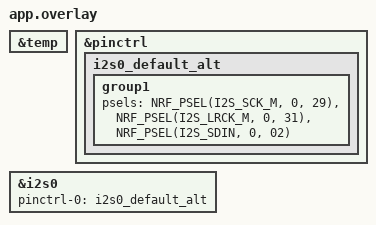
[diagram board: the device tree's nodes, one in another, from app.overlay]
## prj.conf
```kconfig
# BLE
CONFIG_BT=y #enable bluetooth 
CONFIG_LOG=y #Logging
CONFIG_BT_LOG_LEVEL_WRN=y
CONFIG_BT_PERIPHERAL=y #enable periphery service
CONFIG_BT_DEVICE_NAME="Temp and Light" # name used in advertising
CONFIG_BT_DEVICE_APPEARANCE=833 

# SENSORS 
CONFIG_SENSOR=y
CONFIG_TEMP_NRF5=y

# Secure FOTA 
# CONFIG_BOOTLOADER_MCUBOOT=y

# Audio configs 
CONFIG_I2S=y

# DSP Configs
CONFIG_REQUIRES_FULL_LIBC=y
CONFIG_REQUIRES_FLOAT_PRINTF=y
CONFIG_CMSIS_DSP=y
CONFIG_CMSIS_DSP_STATISTICS=y
CONFIG_CMSIS_DSP_FILTERING=y
CONFIG_CBPRINTF_FP_SUPPORT=y
CONFIG_CMSIS_DSP_TRANSFORM=y

# State Machine Configs
CONFIG_SMF=y
```

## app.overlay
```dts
&temp {
	status = "okay"; 
};


&pinctrl {
	/*Assign pins to i2s so we can use mic*/
	i2s0_default_alt: i2s0_default_alt {
		group1 {
			psels = <NRF_PSEL(I2S_SCK_M, 0, 29)>,
				<NRF_PSEL(I2S_LRCK_M, 0, 31)>,
				<NRF_PSEL(I2S_SDIN, 0, 02)>;
		};
	};
};


/*Activate the i2s peripheral by setting status to ok*/
&i2s0{
	status = "okay";
	pinctrl-0 = <&i2s0_default_alt>;
	pinctrl-names = "default";
};
```

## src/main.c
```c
/*
 * Copyright (c) gaiaochos.com
 * SPDX-License-Identifier: Apache-2.0
 */
#include <zephyr/device.h>
#include <zephyr/kernel.h>
#include <zephyr/logging/log.h>

#include "app.h"
#include "audio_service.h"
#include "ble_service.h"
#include "temperature.h"
#include "fsm_service.h"
#include "inference_service.h"

// Enable logs
LOG_MODULE_REGISTER(custom_service_log);

#define THREAD_STACK_SIZE 1024

K_MSGQ_DEFINE(tempmsgq, TEMP_MSG_SIZE, TEMPQSIZE, 2);
K_THREAD_DEFINE(temp_thread_id, THREAD_STACK_SIZE, temp_sensor_thread, NULL, NULL, NULL, 5, 0, 0); 
K_THREAD_DEFINE(ble_temp_thread_id, THREAD_STACK_SIZE, ble_temp_read_thread, NULL, NULL, NULL, 6, 0,0);
K_THREAD_DEFINE(audio_thread_id, THREAD_STACK_SIZE, audio_sense_thread, NULL, NULL, NULL, 4, 0, 0);
K_THREAD_DEFINE(fsm_thread_id, THREAD_STACK_SIZE, fsm_run_thread, NULL, NULL, NULL, 3, 0 , 0);
K_THREAD_DEFINE(inference_thread_id, THREAD_STACK_SIZE, inference_thread_run, NULL, NULL, NULL, 6, 0, 0);
int main(void) { 
   /*State Machine*/
   fsm_init();

  /*Blocking bluetooth init*/
  ble_service_init();

  /*Bluetooth setup was a success do sensor now*/
  sensor_temp_sensor_init();

  /*Inference Thread Init*/
  inference_init();

  /*Audio Service init*/
  audio_service_init();
 
  /*This becomes our idle loop*/
  while (1) {
    k_sleep(K_SECONDS(2));
  }
}
```

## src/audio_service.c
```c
#include <zephyr/logging/log.h>

#include "audio_service.h"
#include "fsm_service.h"

LOG_MODULE_REGISTER(audio_module);

K_MEM_SLAB_DEFINE_STATIC(mem_slab, BLOCK_SIZE, BLOCK_COUNT, 4);
K_MEM_SLAB_DEFINE(inference_slab, BLOCK_SIZE, BLOCK_COUNT, 4);
K_FIFO_DEFINE(infer_fifo);


static const struct device *i2s_dev;

void audio_service_init()
{
	i2s_dev = DEVICE_DT_GET(DT_NODELABEL(i2s0));
	struct i2s_config config;
	int ret;

	config.word_size = SAMPLE_BIT_WIDTH;
	config.channels = NUMBER_OF_CHANNELS;
	config.format = I2S_FMT_DATA_FORMAT_I2S;
	config.options = I2S_OPT_BIT_CLK_MASTER | I2S_OPT_FRAME_CLK_MASTER;
	config.frame_clk_freq = SAMPLE_FREQUENCY;
	config.mem_slab = &mem_slab;
	config.block_size = BLOCK_SIZE;
	config.timeout = TIMEOUT_MS;

	ret = i2s_configure(i2s_dev, I2S_DIR_RX, &config);
	if (ret < 0) {
		LOG_ERR("Failed to configure I2S RX: %d\n", ret);
		return;
	}

	if (!device_is_ready(i2s_dev)) {
		LOG_ERR("I2S device not ready\n");
		return;
	}
}

void audio_sense_thread(void *arg1, void *arg2, void *arg3)
{
	int ret;

	while (1) {
		/*Wait on a semaphore*/
		k_sem_take(&mic_sense_gate, K_FOREVER);

		/* Post an Event to FSM to show MIC capturing*/
		fsm_post_event(EVENT_AUD_SENSE_STARTED);



		/*Check the audio sense gate before working*/
		void *mem_block;
		void *infer_block;
		uint32_t size;

		ret = i2s_trigger(i2s_dev, I2S_DIR_RX, I2S_TRIGGER_START);
		if (ret < 0) {
			LOG_ERR("Failed to start I2S RX: %d \n", ret);
			return;
		}

		LOG_WRN("SENSING AUDIO");
		ret = i2s_read(i2s_dev, &mem_block, &size);
		if (ret == 0) {
			for (int b = 1; b <= 3; b++) {
				ret = k_mem_slab_alloc(&inference_slab, (void **)&infer_block,
						       K_NO_WAIT);
				if (ret == 0) {
					memset(infer_block, 0, size); 
					memcpy(infer_block, mem_block, size);
					k_fifo_put(&infer_fifo, infer_block);
					k_mem_slab_free(&mem_slab, (void *)mem_block);
				} else {
					LOG_ERR("Could not allocate Infer block (%d)", ret);
				}
			}

		} else {
			LOG_ERR("I2S Failed to read %d", ret);
		}

		// 3. Stop capture, then drop any packes
		i2s_trigger(i2s_dev, I2S_DIR_RX, I2S_TRIGGER_STOP);
		i2s_trigger(i2s_dev, I2S_DIR_RX, I2S_TRIGGER_DROP);

		// 4. Sleep before next cycle
		k_sem_give(&mic_sense_gate);
		//SEND A STATE EVENT TO TRIGGER FILTERING
		fsm_post_event(EVENT_AUD_SENSE_END);
		k_sleep(K_SECONDS(2));
	}
}
```

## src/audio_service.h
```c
#ifndef AUDIO_SERVICE_H
#define AUDIO_SERVIC_H
#include <zephyr/device.h>
#include <zephyr/drivers/i2s.h>

#define SAMPLE_FREQUENCY 	44100
/*Mic data sheet*/
#define SAMPLE_BIT_WIDTH 	24
/*24 Bits packed into a 32 bit block*/
#define BYTES_PER_SAMPLE 	sizeof(int32_t)
#define NUMBER_OF_CHANNELS 	1
/*4410 samples so 0.1s
 * Swapped to 4096 because our FFT implementation demands that.
 * */
#define SAMPLES_PER_BLOCK 	4096 //((SAMPLE_FREQUENCY / 10) * NUMBER_OF_CHANNELS)
#define INITIAL_BLOCK_COUNT 	1
#define TIMEOUT_MS 		2000

/*Because i2s_read expects number of bytes*/
#define BLOCK_SIZE 		(BYTES_PER_SAMPLE * SAMPLES_PER_BLOCK) 
/*Enough for 400ms of sound*/
#define BLOCK_COUNT		(INITIAL_BLOCK_COUNT + 3)


/*Filter  Definitions*/
#define NUM_TAPS			53

extern struct k_mem_slab inference_slab;
extern struct k_fifo infer_fifo; 

void audio_service_init();
void audio_sense_thread(void *arg1, void *arg2, void *arg3);
#endif
```

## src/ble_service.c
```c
#include "zephyr/bluetooth/conn.h"
#include <zephyr/bluetooth/bluetooth.h>
#include <zephyr/bluetooth/gatt.h>
#include <zephyr/bluetooth/uuid.h>
#include <zephyr/logging/log.h>
LOG_MODULE_REGISTER(ble_module);

#include "app.h"
#include "ble_service.h"
#include "fsm_service.h"


extern struct state_object state_object;
extern struct k_msgq tempmsgq;

volatile bool ble_ready = false;
float temp_float;

/* Error checking function to make sure ble runs well.
 * Enables us to report on Bluetooth
 */
void bt_ready(int err) {
  if (err) {
    LOG_ERR("bt enable return %d", err);
  }
  LOG_INF("bt ready!");
  ble_ready = true;
}

/* Defining the advertising packets
 * An advertising packet has
 * 1. The name of the service
 * 2. Connection paramters such as intervals
 */
static const struct bt_data advert[] = {
    // enable ble and stop classic bluetooth
    BT_DATA_BYTES(BT_DATA_FLAGS, (BT_LE_AD_GENERAL | BT_LE_AD_NO_BREDR)),
    // our device name
    BT_DATA(BT_DATA_NAME_COMPLETE, CONFIG_BT_DEVICE_NAME,
            sizeof(CONFIG_BT_DEVICE_NAME) - 1),
};

/* Define a BLE service
 * takes name, primary service and secondary service
 * you can have multiple primary services
 * assign permissions
 * point to function to read
 */
BT_GATT_SERVICE_DEFINE(
    enviromental_sensing, BT_GATT_PRIMARY_SERVICE(BT_UUID_DECLARE_16(0x181A)),
    BT_GATT_CHARACTERISTIC(BT_UUID_DECLARE_16(0x2A6E),
                           BT_GATT_CHRC_READ | BT_GATT_CHRC_NOTIFY,
                           BT_GATT_PERM_READ, read_custom_characteristic, NULL,
                           &temp_float));

/* function to read characteristic
 * needs to be type defined as follows
 * this function is read in the rx thread and is blocking so use it like an ISR
 */
ssize_t read_custom_characteristic(struct bt_conn *conn,
                                   const struct bt_gatt_attr *attr, void *buf,
                                   uint16_t len, uint16_t offset) {
  LOG_WRN("Temp was read by Central\n");
  float *value = attr->user_data;
  return bt_gatt_attr_read(conn, attr, buf, len, offset, value, sizeof(*value));
}

/* COnnection Callbacks*/
static void connected(struct bt_conn *conn, uint8_t err) {
	if(err != 0) {
		LOG_ERR("Error occured when connecting (%d)", err);
		/* Should we die */
	}
	LOG_WRN("Connection estalished!"); 
	/* Post an Event to FSM to show connected*/
	fsm_post_event(EVENT_CENTRAL_CONNECTED);
}

static void disconnected(struct bt_conn *conn, uint8_t err) {
	if(err != 0) {
		LOG_ERR("Error occured when disconnecting (%d)", err); 
		/*Should we die?*/
	}
	LOG_WRN("Disconnection finished");
	/*Post an event to the FSM that we are disconnected*/
	fsm_post_event(EVENT_CENTRAL_DISCONNECTED);
}

static struct bt_conn_cb our_callbacks = {
	.connected = connected, 
	.disconnected = disconnected,
};


void ble_service_init(void) {
  int err;

  /*Initialize BLE and wait until it is done*/
  err = bt_enable(bt_ready);
  while (!ble_ready) {
    LOG_WRN("bt not ready!");
    k_msleep(100);
  }

  /* Register  connection callbacks*/
  err = bt_conn_cb_register(&our_callbacks);
  if (err != 0U ) {
	  LOG_ERR("Connection callbacks could not be registered");
	  /* how to handle failure*/
  }

  /*Low Power advertising params*/
  struct bt_le_adv_param lp_adv_params = {
	  .options = BT_LE_ADV_OPT_CONN,
	  .interval_min = 1600, 
	  .interval_max = 2000,
  };

  /*When ready register callbacks to handle connections and notifications*/
  err = bt_le_adv_start(&lp_adv_params, advert, ARRAY_SIZE(advert), NULL, 0);
  if (err) {
    LOG_ERR("advertising failed to start 0x%02x", err);
  }
}


/*BLE Threads*/

/*Read Current Temp Thread*/
void ble_temp_read_thread(void *arg1, void *arg2, void *arg3) {
	while(1) {
		/*Try to read the queue until it has something*/
		if (k_msgq_get(&tempmsgq, &curr_msg, K_FOREVER) == 0 ) {
			temp_float = curr_msg.value;
		}

		//Wait 10s 
		k_sleep(K_SECONDS(5));
	}
}
```

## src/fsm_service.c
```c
#include <zephyr/logging/log.h>
#include <zephyr/smf.h>

#include "fsm_service.h"
#include "zephyr/kernel.h"

LOG_MODULE_REGISTER(fsm_module);

/*App Gates*/
K_SEM_DEFINE(temp_sense_gate, 0, 1);
K_SEM_DEFINE(mic_sense_gate, 0, 1);
K_SEM_DEFINE(inference_gate, 0, 1);

/*End Gates*/

static const struct smf_state ble_app_states[];

enum ble_app_state {
	IDLE,
	CONNECTED,
	TEMP_READ,
	MIC_CAPTURE,
	INFERING,
	ERROR
};

struct state_object {
	/*Must be first for  casting*/
	struct smf_ctx state_context;

	/*Rest of the State Stuff*/
	struct k_event smf_event;
	int32_t events;

} state_object;

// idle
static void idle_entry(void *o)
{
	LOG_WRN("Entered Idle");
	k_sem_reset(&mic_sense_gate);
	k_sem_reset(&temp_sense_gate);
}
static enum smf_state_result idle_run(void *o)
{
	struct state_object *so = o;

	/*Wait for connect*/
	if (so->events & EVENT_CENTRAL_CONNECTED) {
		LOG_WRN("Go to connected State");
		smf_set_state(SMF_CTX(&so->state_context), &ble_app_states[CONNECTED]);
	}
	return SMF_EVENT_HANDLED;
}
static void idle_exit(void *o)
{
	LOG_WRN("Left Idle");
}

// connected
static void connected_entry(void *o)
{
	LOG_WRN("Entering Connected state");
	/*Once connected open the sense gates*/
	k_sem_give(&mic_sense_gate);
	k_sem_give(&temp_sense_gate);

}

static enum smf_state_result connected_run(void *o)
{
	struct state_object *so = o;
	if (so->events & EVENT_CENTRAL_DISCONNECTED) {
		LOG_WRN("Go to connected State");
		smf_set_state(SMF_CTX(&so->state_context), &ble_app_states[IDLE]);
	} else if (so->events & EVENT_AUD_SENSE_STARTED) {
		LOG_WRN("Go to MIC Capture State");
		smf_set_state(SMF_CTX(&so->state_context), &ble_app_states[MIC_CAPTURE]);
	}
	return SMF_EVENT_HANDLED;
}

static void connected_exit(void *o)
{
	LOG_WRN("Left Connnected");
}

// temp  read

static void temp_read_entry(void *o)
{
	LOG_WRN("Entered Temp_Read");
}
static enum smf_state_result temp_read_run(void *o)
{
	smf_set_state(SMF_CTX(&state_object), &ble_app_states[TEMP_READ]);
	return SMF_EVENT_HANDLED;
}

// mic capture
static void mic_capture_entry(void *o)
{
	LOG_WRN("Entered MIC_CAPTURE"); 
	k_sem_take(&inference_gate, K_NO_WAIT);
}
static enum smf_state_result mic_capture_run(void *o)
{

	struct state_object *so = o;
	if (so->events & EVENT_AUD_SENSE_END) {
		LOG_WRN("Go to Infering State");
		smf_set_state(SMF_CTX(&so->state_context), &ble_app_states[INFERING]);
	}
	return SMF_EVENT_HANDLED;
}

static void mic_capture_exit(void *o)
{
	LOG_WRN("Left MIC Capture");
	k_sem_give(&inference_gate);
	
}



static void infering_entry(void *o)
{
	LOG_WRN("Entered INFERING");
	k_sem_take(&mic_sense_gate, K_NO_WAIT);
}
static enum smf_state_result infering_run(void *o)
{
	struct state_object *so = o;
	if (so->events & EVENT_INFERENCE_END) {
		LOG_WRN("Go to Connected State");
		smf_set_state(SMF_CTX(&so->state_context), &ble_app_states[CONNECTED]);
	}
	return SMF_EVENT_HANDLED;
}
static void infering_exit(void *o)
{
	LOG_WRN("Left Infering");
	k_sem_give(&mic_sense_gate);
}





// error state

static void error_entry(void *o)
{
	LOG_WRN("Entered Error");
}
static enum smf_state_result error_run(void *o)
{
	// Do computation here to determine if you want to be here or not
	// or cause some side effect
	smf_set_state(SMF_CTX(&state_object), &ble_app_states[ERROR]);
	return SMF_EVENT_HANDLED;
}

// make a state table
static const struct smf_state ble_app_states[] = {
	[IDLE] = SMF_CREATE_STATE(idle_entry, idle_run, idle_exit, NULL, NULL),
	[CONNECTED] = SMF_CREATE_STATE(connected_entry, connected_run, connected_exit, NULL, NULL),
	[TEMP_READ] = SMF_CREATE_STATE(temp_read_entry, temp_read_run, NULL, NULL, NULL),
	[MIC_CAPTURE] = SMF_CREATE_STATE(mic_capture_entry, mic_capture_run, mic_capture_exit, NULL, NULL),
	[INFERING] = SMF_CREATE_STATE(infering_entry, infering_run, infering_exit, NULL, NULL),
	[ERROR] = SMF_CREATE_STATE(error_entry, error_run, NULL, NULL, NULL),
};

struct fsm_event {
	uint32_t events;
};

K_MSGQ_DEFINE(fsm_event_q, sizeof(struct fsm_event), 10, 1);

int fsm_post_event(uint32_t events)
{
	LOG_WRN("INCOMING EVENT 0x%08x", events);
	struct fsm_event ev = {
		.events = events,
	};
	return k_msgq_put(&fsm_event_q, &ev, K_NO_WAIT);
}

void fsm_init(void)
{
	/*Initialize events*/
	k_event_init(&state_object.smf_event);

	smf_set_initial(SMF_CTX(&state_object), &ble_app_states[IDLE]);
}

void fsm_run_thread(void *arg1, void *arg2, void *arg3)
{
	while (1) {
		struct fsm_event ev;
		int rc = k_msgq_get(&fsm_event_q, &ev, K_FOREVER);
		if (rc != 0) {
			continue;
		}

		state_object.events = ev.events;

		int ret = smf_run_state(SMF_CTX(&state_object));
		if (ret != 0) {
			LOG_ERR("FSM exploded (%d)", ret);
			break;
		}
	}
}
```

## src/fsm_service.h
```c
#ifndef FSM_SERVICE_H
#define FSM_SERVICE_H
#include <zephyr/sys/util.h>

/*List of App Events & Gates*/
#define EVENT_CENTRAL_CONNECTED    BIT(0)
#define EVENT_TEMP_READ            BIT(1)
#define EVENT_AUDIO_DETECTED       BIT(2)
#define EVENT_ERROR_OCCURED        BIT(3)
#define EVENT_CENTRAL_DISCONNECTED BIT(4)
#define EVENT_AUD_SENSE_STARTED    BIT(5)
#define EVENT_AUD_SENSE_END	   BIT(6)
#define EVENT_INFERENCE_START	   BIT(7)
#define EVENT_INFERENCE_END 	   BIT(8)

extern struct k_sem temp_sense_gate;
extern struct k_sem mic_sense_gate;
extern struct k_sem inference_gate;

/*End List Events & gates*/
void fsm_init(void);
int fsm_post_event(uint32_t events);
void fsm_run_thread(void *arg1, void *arg2, void *arg3);
#endif
```

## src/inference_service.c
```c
#include <zephyr/logging/log.h> 
#include <arm_math.h>

#include "dsp/transform_functions.h"
#include "inference_service.h"
#include "fsm_service.h"
#include "audio_service.h"

LOG_MODULE_REGISTER(inference_module);

static float32_t fir_state[SAMPLES_PER_BLOCK + NUM_TAPS - 1];
float32_t samples_f[SAMPLES_PER_BLOCK];
float32_t fft_samples[SAMPLES_PER_BLOCK];
float32_t filtered_samples[SAMPLES_PER_BLOCK];

const float32_t filter_taps[NUM_TAPS] = {
	0.000000008f,         -0.000000017f,        -0.000005158008031f,  0.000001306510464f,
	0.000133311671510f,   0.000441338085554f,   -0.000003558565317f,  -0.004678776861470f,
	-0.019949989253140f,  -0.050762976431733f,  -0.089992776291018f,  -0.106658945543195f,
	-0.047616537578776f,  0.128400969571106f,   0.268940032322269f,   0.462916716560925f,
	1.178737310340750f,   1.424457502062019f,   -3.207525353661072f,  -19.048378444758412f,
	-47.055221581646288f, -74.530801502545513f, -76.819606475710525f, -34.360189603714439f,
	45.911370731458956f,  126.083204431962914f, 159.765576060044795f, 126.083204431961582f,
	45.911370731459150f,  -34.360189603714272f, -76.819606475710567f, -74.530801502545402f,
	-47.055221581646260f, -19.048378444758388f, -3.207525353661006f,  1.424457502062048f,
	1.178737310340738f,   0.462916716560904f,   0.268940032322248f,   0.128400969571093f,
	-0.047616537578774f,  -0.106658945543187f,  -0.089992776290978f,  -0.050762976431705f,
	-0.019949989253143f,  -0.004678776861483f,  -0.000003558565316f,  0.000441338085556f,
	0.000133311671509f,   0.000001306510473f,   -0.000005158008016f,  0.000000001f,
	0.000000008f};
/*End Coefficients*/


void inference_init() {
	LOG_WRN("Inference initialized"); 
}

void inference_thread_run(void *arg1, void *arg2,  void *arg3) {
	arm_rfft_fast_instance_f32 FFT_INST;
	int fft_flag = 0;
	arm_status fft_s = arm_rfft_fast_init_4096_f32(&FFT_INST);
	LOG_WRN("FFT Init status  %d", fft_s);

	while(1) {
		k_sem_take(&inference_gate, K_FOREVER);
		LOG_WRN("Inference has been run");


		for (int b = 0; b < 3; b++) {
			void *rx_block = k_fifo_get(&infer_fifo, K_NO_WAIT);
			//1.normalize samples 
			int32_t *samples = rx_block;
			
			//Normalize sample
			
			for(int f = 0; f < SAMPLES_PER_BLOCK; f++)
			{
				// convert to float32
				int32_t  sam = samples[f] >> 8; 
				float32_t f_sample = (float32_t)sam / 8388608.0f;
				samples_f[f] = f_sample;
			}
			//2. Compute FFT of samples 
			arm_rfft_fast_f32(&FFT_INST, samples_f, fft_samples, fft_flag); 

			
			for(int f = 0; f < 100; f++)
			{
				LOG_ERR("FFT Sample %d: %f", f, 
						(double)fft_samples[f]);
			}
			
			// 4. Free each block
			k_mem_slab_free(&inference_slab, (void *)rx_block);

		}
		
		// 5 Use hysteresis  to check for clap


				// Apply Filter
				
			
				

		k_sem_give(&inference_gate);
		fsm_post_event(EVENT_INFERENCE_END);
		k_sleep(K_SECONDS(4)); 
	}
}
```

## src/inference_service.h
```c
#ifndef INFERENCE_SERVICE_H
#define INFERENCE_SERVICE_H

#ifdef __cplusplus 
extern "C" {
#endif

void inference_init();
void inference_thread_run(void *arg1, void *arg2, void *arg3);
#endif
```

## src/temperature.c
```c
#include <zephyr/drivers/sensor.h>
#include <zephyr/kernel.h>
#include <zephyr/logging/log.h>
#include <zephyr/sys/printk.h>

#include "app.h"
#include "temperature.h"

LOG_MODULE_REGISTER(temperature_module);

extern struct k_msgq tempmsgq;

struct current_temp_msg curr_msg;

static const struct device *temp_sensor;


void sensor_temp_sensor_init() { 
	 temp_sensor = DEVICE_DT_GET_ANY(nordic_nrf_temp);

  if (!temp_sensor || !device_is_ready(temp_sensor)) {
    LOG_ERR("Device (%s) is not ready", temp_sensor->name);
  }

}

/* Define a Routine to collect sensor readings */
double fetch_temp(const struct device *sensor) {
  struct sensor_value temp;
  int rc = sensor_sample_fetch(sensor);

  if (rc == -EBADMSG) {
    /*In polling we don't care*/
    rc = 0;
  }

  if (rc == 0U) {
    rc = sensor_channel_get(sensor, SENSOR_CHAN_DIE_TEMP, &temp);
  }

  if (rc != 0U) {
    LOG_ERR("Error: Getting Temp channel fromsensor (%d)", rc);
  }

  return sensor_value_to_double(&temp);
}

/*define a thread to read temps every 2s*/
void temp_sensor_thread(void *arg1 , void *arg2, void *arg3) 
{
	while(1) {
		/*Check the temp sense gate before running*/
		float curr_temp = (float)fetch_temp(temp_sensor); 
		curr_msg.value  = curr_temp;

		/*Push the work  into the queue*/
		if (k_msgq_put(&tempmsgq, &curr_msg, K_NO_WAIT) != 0) {
			//Queue is full here  drop the oldest 
			LOG_WRN("Temp  Q was full dropping oldest \n");
			struct current_temp_msg throwaway; 
			k_msgq_get(&tempmsgq, &throwaway, K_NO_WAIT);
			k_msgq_put(&tempmsgq, &curr_msg, K_NO_WAIT); 
		}

		/*Wait 2 seconds and run again*/
		k_sleep(K_SECONDS(2));	
	}
}
```
